VERSION ""

NS_ :

BS_:

BU_: BCM Instrumentcluster Gateway

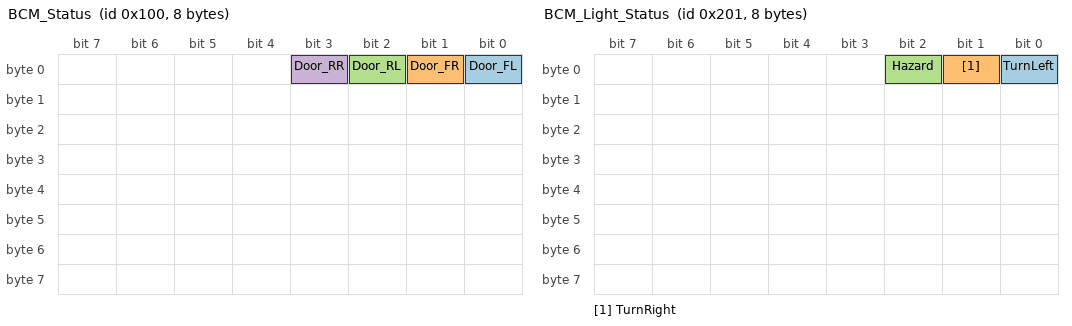
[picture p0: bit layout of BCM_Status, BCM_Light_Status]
BO_ 256 BCM_Status: 8 BCM
 SG_ Door_FL : 0|1@1+ (1,0) [0|1] ""  Instrumentcluster,Gateway
 SG_ Door_FR : 1|1@1+ (1,0) [0|1] ""  Instrumentcluster,Gateway
 SG_ Door_RL : 2|1@1+ (1,0) [0|1] ""  Instrumentcluster,Gateway
 SG_ Door_RR : 3|1@1+ (1,0) [0|1] ""  Instrumentcluster,Gateway

BO_ 513 BCM_Light_Status: 8 BCM
 SG_ TurnLeft : 0|1@1+ (1,0) [0|1] ""  Gateway,Instrumentcluster
 SG_ TurnRight : 1|1@1+ (1,0) [0|1] ""  Instrumentcluster,Gateway
 SG_ Hazard : 2|1@1+ (1,0) [0|1] ""  Instrumentcluster,Gateway

BA_DEF_  "BusType" STRING ;
BA_DEF_DEF_  "BusType" "CAN";
